VERSION ""

NS_ :

BS_:

BU_: ECU_Student ECU_Infotainment

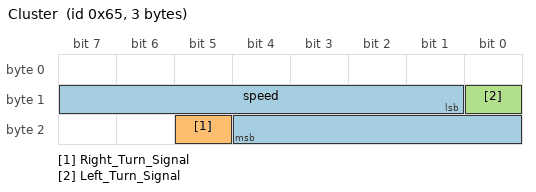
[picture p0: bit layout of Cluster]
BO_ 101 Cluster: 3 ECU_Student
 SG_ speed : 9|12@1+ (1,0) [0|4095] "" Vector__XXX
 SG_ Right_Turn_Signal : 21|1@1+ (1,0) [0|1] "" Vector__XXX
 SG_ Left_Turn_Signal : 8|1@1+ (1,0) [0|1] "" Vector__XXX

BA_DEF_  "BusType" STRING ;
BA_DEF_DEF_  "BusType" "CAN";
